# ATmega162 device description
Architecture: AVR8; Family: megaAVR
Registers are 8-bit, access not given, no defined reset value unless marked. A register's access mark holds for its fields unless they carry their own. Offsets are from the block's base; [hi:lo] are bit positions.

## AC — Analog Comparator
Instances: AC 0x00
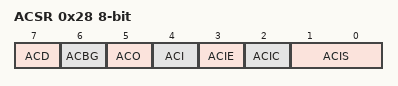
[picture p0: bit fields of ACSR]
0x28 ACSR — Analog Comparator Control And Status Register
  [7] ACD — Analog Comparator Disable
  [6] ACBG — Analog Comparator Bandgap Select
  [5] ACO — Analog Compare Output
  [4] ACI — Analog Comparator Interrupt Flag
  [3] ACIE — Analog Comparator Interrupt Enable
  [2] ACIC — Analog Comparator Input Capture Enable
  [1:0] ACIS — Analog Comparator Interrupt Mode Select bits
    0=Interrupt on Toggle; 2=Interrupt on Falling Edge; 3=Interrupt on Rising Edge

## USART0 — USART
Instances: USART0 0x00
0x29 UBRR0L — USART Baud Rate Register Low Byte
  [7:0] UBRR0 — USART Baud Rate Register Low bits
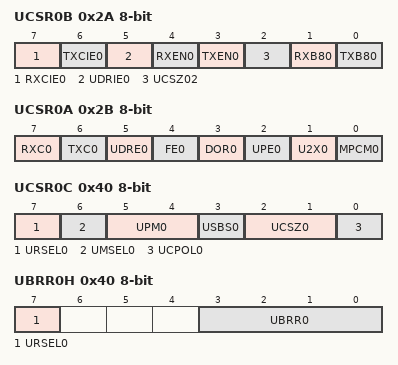
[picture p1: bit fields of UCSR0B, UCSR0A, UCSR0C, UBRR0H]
0x2A UCSR0B — USART Control and Status Register B
  [7] RXCIE0 — RX Complete Interrupt Enable
  [6] TXCIE0 — TX Complete Interrupt Enable
  [5] UDRIE0 — USART Data register Empty Interrupt Enable
  [4] RXEN0 — Receiver Enable
  [3] TXEN0 — Transmitter Enable
  [2] UCSZ02 — Character Size
  [1] RXB80 — Receive Data Bit 8
  [0] TXB80 — Transmit Data Bit 8
0x2B UCSR0A — USART Control and Status Register A
  [7] RXC0 — USART Receive Complete
  [6] TXC0 — USART Transmitt Complete
  [5] UDRE0 — USART Data Register Empty
  [4] FE0 — Framing Error
  [3] DOR0 — Data overRun
  [2] UPE0 — Parity Error
  [1] U2X0 — Double the USART transmission speed
  [0] MPCM0 — Multi-processor Communication Mode
0x2C UDR0 — USART I/O Data Register
0x40 UCSR0C — USART Control and Status Register C
  [7] URSEL0 — Register Select
  [6] UMSEL0 — USART Mode Select
    0=Asynchronous Operation; 1=Synchronous Operation
  [5:4] UPM0 — Parity Mode Bits
    0=Disabled; 2=Enabled, Even Parity; 3=Enabled, Odd Parity
  [3] USBS0 — Stop Bit Select
    0=1-bit; 1=2-bit
  [2:1] UCSZ0 — Character Size
  [0] UCPOL0 — Clock Polarity
0x40 UBRR0H — USART Baud Rate Register High Byte
  [7] URSEL0 — Register Select
  [3:0] UBRR0 (bit 8 of the value upward) — USART Baud Rate Register High bits

## USART1 — USART
Instances: USART1 0x00
0x20 UBRR1L — USART Baud Rate Register Low Byte
  [7:0] UBRR1 — USART Baud Rate Register Low bits
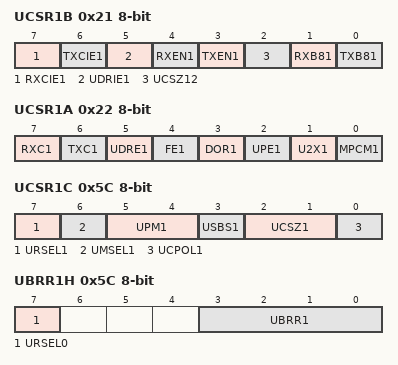
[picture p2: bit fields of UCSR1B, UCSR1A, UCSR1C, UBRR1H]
0x21 UCSR1B — USART Control and Status Register B
  [7] RXCIE1 — RX Complete Interrupt Enable
  [6] TXCIE1 — TX Complete Interrupt Enable
  [5] UDRIE1 — USART Data register Empty Interrupt Enable
  [4] RXEN1 — Receiver Enable
  [3] TXEN1 — Transmitter Enable
  [2] UCSZ12 — Character Size
  [1] RXB81 — Receive Data Bit 8
  [0] TXB81 — Transmit Data Bit 8
0x22 UCSR1A — USART Control and Status Register A
  [7] RXC1 — USART Receive Complete
  [6] TXC1 — USART Transmitt Complete
  [5] UDRE1 — USART Data Register Empty
  [4] FE1 — Framing Error
  [3] DOR1 — Data overRun
  [2] UPE1 — Parity Error
  [1] U2X1 — Double the USART transmission speed
  [0] MPCM1 — Multi-processor Communication Mode
0x23 UDR1 — USART I/O Data Register
0x5C UCSR1C — USART Control and Status Register C
  [7] URSEL1 — Register Select
  [6] UMSEL1 — USART Mode Select
    0=Asynchronous Operation; 1=Synchronous Operation
  [5:4] UPM1 — Parity Mode Bits
    0=Disabled; 2=Enabled, Even Parity; 3=Enabled, Odd Parity
  [3] USBS1 — Stop Bit Select
    0=1-bit; 1=2-bit
  [2:1] UCSZ1 — Character Size
  [0] UCPOL1 — Clock Polarity
0x5C UBRR1H — USART Baud Rate Register Highg Byte
  [7] URSEL0 — Register Select
  [3:0] UBRR1 (bit 8 of the value upward) — USART Baud Rate Register High bits

## SPI — Serial Peripheral Interface
Instances: SPI 0x00
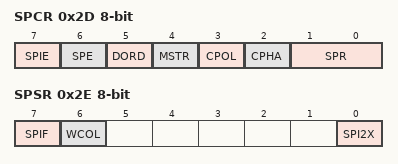
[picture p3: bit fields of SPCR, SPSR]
0x2D SPCR — SPI Control Register
  [7] SPIE — SPI Interrupt Enable
  [6] SPE — SPI Enable
  [5] DORD — Data Order
  [4] MSTR — Master/Slave Select
  [3] CPOL — Clock polarity
  [2] CPHA — Clock Phase
  [1:0] SPR — SPI Clock Rate Selects
    0=fosc/4; 1=fosc/16; 2=fosc/64; 3=fosc/128; 4=fosc/2; 5=fosc/8; 6=fosc/32; 7=fosc/64
0x2E SPSR — SPI Status Register
  [7] SPIF — SPI Interrupt Flag
  [6] WCOL — Write Collision Flag
  [0] SPI2X — Double SPI Speed Bit
0x2F SPDR — SPI Data Register
